# WKUP_CTRL_MMR0_WKUP_CTRL_MMR0_ID_MMRS_43000000h register map
Vendor: Texas Instruments
Peripheral module from a debugger description file (folder am62L).
Registers are 32-bit, read-only, reset 0x0 unless marked. A register's access mark holds for its fields unless they carry their own. Offsets are as the file gives them; lines under a group give offsets from that group; [hi:lo] are bit positions; {n}, {i} and the like mark numbered series; 'fields as' and 'values as' point back to an identical list; <NAME> marks a mode.

## WKUP_CTRL_MMR0_ID_MMRS
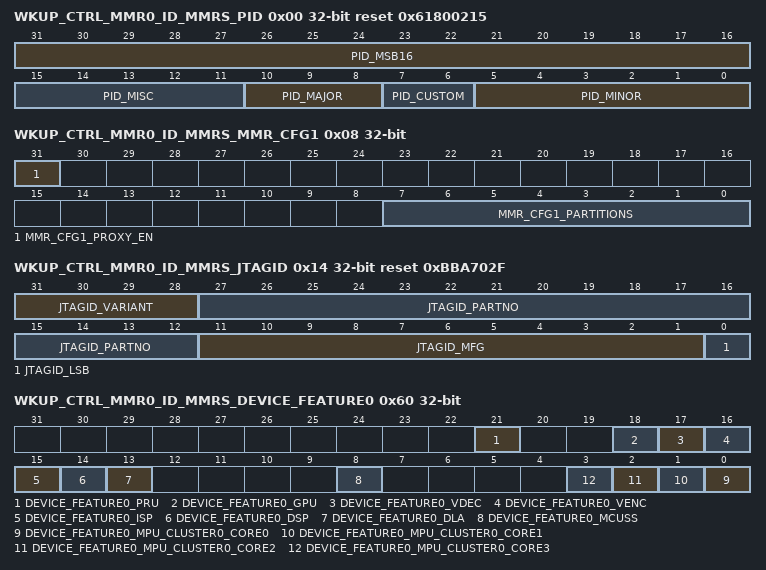
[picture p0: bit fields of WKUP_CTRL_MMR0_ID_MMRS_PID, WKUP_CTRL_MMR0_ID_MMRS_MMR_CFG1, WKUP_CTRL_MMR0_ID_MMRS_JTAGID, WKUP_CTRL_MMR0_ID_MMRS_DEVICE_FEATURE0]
0x00 WKUP_CTRL_MMR0_ID_MMRS_PID reset 0x61800215
  [31:16] PID_MSB16 — Reset Source: mod_g_rst_n
  [15:11] PID_MISC — Reset Source: mod_g_rst_n
  [10:8] PID_MAJOR — Reset Source: mod_g_rst_n
  [7:6] PID_CUSTOM — Reset Source: mod_g_rst_n
  [5:0] PID_MINOR — Reset Source: mod_g_rst_n
0x08 WKUP_CTRL_MMR0_ID_MMRS_MMR_CFG1 — Indicates the MMR configuration
  [31] MMR_CFG1_PROXY_EN — No Proxy Addressing Reset Source: mod_por_rst_n
  [7:0] MMR_CFG1_PARTITIONS — No Partitions Implemented Reset Source: mod_por_rst_n
0x14 WKUP_CTRL_MMR0_ID_MMRS_JTAGID reset 0xBBA702F — The JTAGID register must be readable by the configuration bus so that this can be accessed via the JTAG and CPU. This ID is also readable through Boundary Scan
  [31:28] JTAGID_VARIANT — Used to indicate new PGs Reset Source: mod_por_rst_n
  [27:12] JTAGID_PARTNO — Part number for boundary scan Reset Source: mod_por_rst_n
  [11:1] JTAGID_MFG — Indicates manufacturer Reset Source: mod_por_rst_n
  [0] JTAGID_LSB — Always 1 Reset Source: mod_por_rst_n
0x18 WKUP_CTRL_MMR0_ID_MMRS_JTAG_USER_ID — Additional fuse programmable device identifying information.
  [31:0] JTAG_USER_ID_USERCODE — Device information Reset Source: mod_por_rst_n
0x60 WKUP_CTRL_MMR0_ID_MMRS_DEVICE_FEATURE0 — Indicates presence of features on device
  [21] DEVICE_FEATURE0_PRU — PRU / ICSS Availability 0 NOT_AVAILABLE1 AVAILABLE
  [18] DEVICE_FEATURE0_GPU — GPU Availability 0 NOT_AVAILABLE1 AVAILABLE
  [17] DEVICE_FEATURE0_VDEC — Video Decoder Availability 0 NOT_AVAILABLE1 AVAILABLE
  [16] DEVICE_FEATURE0_VENC — Video Encoder Availability 0 NOT_AVAILABLE1 AVAILABLE
  [15] DEVICE_FEATURE0_ISP — ISP Availability 0 NOT_AVAILABLE1 AVAILABLE
  [14] DEVICE_FEATURE0_DSP — DSP Availability 0 NOT_AVAILABLE1 AVAILABLE
  [13] DEVICE_FEATURE0_DLA — Deep Learning Accelerator Availability 0 NOT_AVAILABLE1 AVAILABLE
  [8] DEVICE_FEATURE0_MCUSS — MCU Availability 0 NOT_AVAILABLE1 AVAILABLE
  [n] DEVICE_FEATURE0_MPU_CLUSTER0_CORE{n} (n=0..3) — MPU Cluster0 Core {n} Availability 0 NOT_AVAILABLE1 AVAILABLE
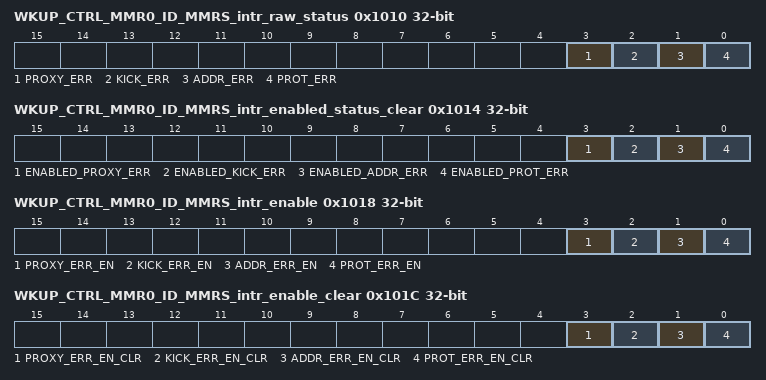
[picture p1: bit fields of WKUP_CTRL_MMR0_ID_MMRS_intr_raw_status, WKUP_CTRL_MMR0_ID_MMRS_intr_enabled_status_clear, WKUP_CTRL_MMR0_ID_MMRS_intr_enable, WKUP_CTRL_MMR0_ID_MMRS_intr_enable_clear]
0x1010 WKUP_CTRL_MMR0_ID_MMRS_intr_raw_status access not given
  [3] PROXY_ERR — Proxy0 access violation error. Raw status is read. Write a 1 to set the status. Writing a 0 has no effect. Reset Source: mod_g_rst_n (access R/W1TS)
  [2] KICK_ERR — Kick access violation error. Raw status is read. Write a 1 to set the status. Writing a 0 has no effect. Reset Source: mod_g_rst_n (access R/W1TS)
  [1] ADDR_ERR — Addressing violation error. Raw status is read. Write a 1 to set the status. Writing a 0 has no effect. Reset Source: mod_g_rst_n (access R/W1TS)
  [0] PROT_ERR — Protection violation error. Raw status is read. Write a 1 to set the status. Writing a 0 has no effect. Reset Source: mod_g_rst_n (access R/W1TS)
0x1014 WKUP_CTRL_MMR0_ID_MMRS_intr_enabled_status_clear access not given
  [3] ENABLED_PROXY_ERR — Proxy0 access violation error. Enabled status is read. Write a 1 to clear the status. Writing a 0 has no effect. Reset Source: mod_g_rst_n (access R/W1TC)
  [2] ENABLED_KICK_ERR — Kick access violation error. Enabled status is read. Write a 1 to clear the status. Writing a 0 has no effect. Reset Source: mod_g_rst_n (access R/W1TC)
  [1] ENABLED_ADDR_ERR — Addressing violation error. Enabled status is read. Write a 1 to clear the status. Writing a 0 has no effect. Reset Source: mod_g_rst_n (access R/W1TC)
  [0] ENABLED_PROT_ERR — Protection violation error. Enabled status is read. Write a 1 to clear the status. Writing a 0 has no effect. Reset Source: mod_g_rst_n (access R/W1TC)
0x1018 WKUP_CTRL_MMR0_ID_MMRS_intr_enable access not given
  [3] PROXY_ERR_EN — Proxy0 access violation error enable. Write a 1 to set the enable. Writing a 0 has no effect. Reset Source: mod_g_rst_n (access R/W1TS)
  [2] KICK_ERR_EN — Kick access violation error enable. Write a 1 to set the enable. Writing a 0 has no effect. Reset Source: mod_g_rst_n (access R/W1TS)
  [1] ADDR_ERR_EN — Addressing violation error enable. Write a 1 to set the enable. Writing a 0 has no effect. Reset Source: mod_g_rst_n (access R/W1TS)
  [0] PROT_ERR_EN — Protection violation error enable. Write a 1 to set the enable. Writing a 0 has no effect. Reset Source: mod_g_rst_n (access R/W1TS)
0x101C WKUP_CTRL_MMR0_ID_MMRS_intr_enable_clear access not given
  [3] PROXY_ERR_EN_CLR — Proxy0 access violation error enable clear. Write a 1 to clear the enable. Writing a 0 has no effect. Reset Source: mod_g_rst_n (access R/W1TC)
  [2] KICK_ERR_EN_CLR — Kick access violation error enable clear. Write a 1 to clear the enable. Writing a 0 has no effect. Reset Source: mod_g_rst_n (access R/W1TC)
  [1] ADDR_ERR_EN_CLR — Addressing violation error enable clear. Write a 1 to clear the enable. Writing a 0 has no effect. Reset Source: mod_g_rst_n (access R/W1TC)
  [0] PROT_ERR_EN_CLR — Protection violation error enable clear. Write a 1 to clear the enable. Writing a 0 has no effect. Reset Source: mod_g_rst_n (access R/W1TC)
0x1020 WKUP_CTRL_MMR0_ID_MMRS_eoi rw
  [7:0] EOI_VECTOR — EOI vector value. Write this with interrupt distribution value in the chip. Reset Source: mod_g_rst_n
0x1024 WKUP_CTRL_MMR0_ID_MMRS_fault_address
  [31:0] FAULT_ADDR — Fault Address. Reset Source: mod_g_rst_n
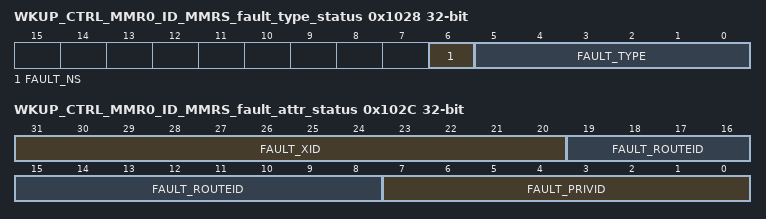
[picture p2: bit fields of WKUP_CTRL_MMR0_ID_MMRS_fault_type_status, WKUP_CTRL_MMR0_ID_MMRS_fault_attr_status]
0x1028 WKUP_CTRL_MMR0_ID_MMRS_fault_type_status
  [6] FAULT_NS — Non-secure access. Reset Source: mod_g_rst_n
  [5:0] FAULT_TYPE — Fault Type 10_0000 = Supervisor read fault - priv = 1 dir = 1 dtype != 1 01_0000 = Supervisor write fault - priv = 1 dir = 0 00_1000 = Supervisor execute fault - priv = 1 dir = 1 dtype = 1 00_0100 = User read fault - priv = 0 dir = 1 dtype = 1 00_0010 = User write fault - priv = 0 dir = 0 00_0001 = User execute fault - priv = 0 dir = 1 dtype = 1 00_0000 = No fault Reset Source: mod_g_rst_n
0x102C WKUP_CTRL_MMR0_ID_MMRS_fault_attr_status
  [31:20] FAULT_XID — XID. Reset Source: mod_g_rst_n
  [19:8] FAULT_ROUTEID — Route ID. Reset Source: mod_g_rst_n
  [7:0] FAULT_PRIVID — Privilege ID. Reset Source: mod_g_rst_n
0x1030 WKUP_CTRL_MMR0_ID_MMRS_fault_clear wo
  [0] FAULT_CLR — Fault clear. Writing a 1 clears the current fault. Writing a 0 has no effect. Reset Source: mod_g_rst_n
0x2000 WKUP_CTRL_MMR0_ID_MMRS_MAC_ID0 rw — Ethernet MAC address lower 32-bits
  [31:0] MAC_ID0_MACID_LO — 32 lsbs of MAC address Reset Source: mod_g_rst_n
0x2004 WKUP_CTRL_MMR0_ID_MMRS_MAC_ID1 rw — Ethernet MAC address upper 16-bits
  [15:0] MAC_ID1_MACID_HI — 16 msbs of MAC address Reset Source: mod_g_rst_n
0x4000 WKUP_CTRL_MMR0_ID_MMRS_USB_DEVICE_ID0 rw reset 0x61650451 — USB device and vendor ID register 0 (ROM Writes)
  [31:0] USB_DEVICE_ID0_ID0 — ROM writes 32-bit Value from Customer OTP to Here Reset Source: mod_g_rst_n
0x4004 WKUP_CTRL_MMR0_ID_MMRS_USB_DEVICE_ID1 rw reset 0x61650451 — USB device and vendor ID register 1 (ROM Writes)
  [31:0] USB_DEVICE_ID1_ID1 — ROM writes 32-bit Value from Customer OTP to Here Reset Source: mod_g_rst_n
{0x5000+4i} WKUP_CTRL_MMR0_ID_MMRS_GP_SW{i} (i=0..2) — Allocated for customer use - Ex. Storage of PID/VID, Model #, Etc.
  [31:0] GP_SW{i}_VAL — general purpose value Reset Source: mod_por_rst_n
0x500C WKUP_CTRL_MMR0_ID_MMRS_GP_SW3 — Allocated for customer use - Ex. Storage of PID/VID, Model #, Etc.
  [3:0] GP_SW3_VAL — general purpose value Reset Source: mod_por_rst_n
